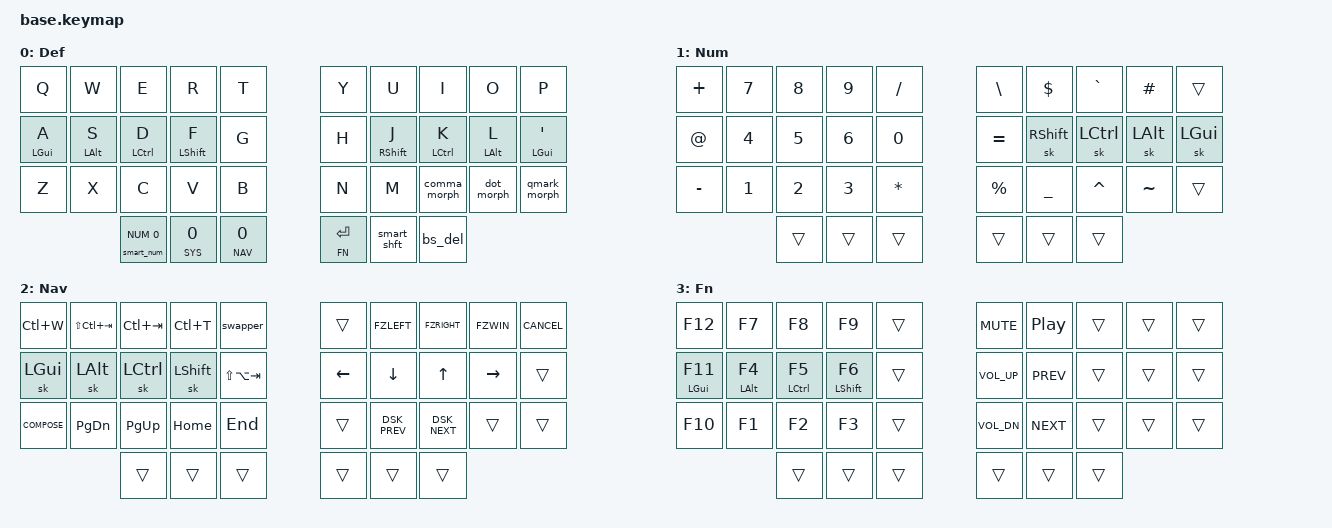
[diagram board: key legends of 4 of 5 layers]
#include <behaviors.dtsi>
#include <dt-bindings/zmk/keys.h>

/* layer and key shortcuts */
#include <dt-bindings/zmk/bt.h>
#include "../zmk-nodefree-config/helper.h"

#define _BT_SEL_KEYS_ &bt BT_SEL 0 &bt BT_SEL 1 &bt BT_SEL 2 &bt BT_SEL 3 &bt BT_CLR

#define DEF 0  // layer shortcuts, must match order in which they are defined below
#define NUM 1
#define NAV 2
#define FN  3
#define SYS 4
// #define MOUSE 5

#define KEYS_L LT0 LT1 LT2 LT3 LT4 LM0 LM1 LM2 LM3 LM4 LB0 LB1 LB2 LB3 LB4  // left hand
#define KEYS_R RT0 RT1 RT2 RT3 RT4 RM0 RM1 RM2 RM3 RM4 RB0 RB1 RB2 RB3 RB4  // right hand
#define KEYS_T LH2 LH1 LH0 RH0 RH1 RH2   // thumbs


#include "includes/macros.dtsi"
#include "includes/mods.dtsi"
#include "includes/dance.dtsi"
#include "includes/morphs.dtsi" // requires layer aliases
// #include "includes/mouse.dtsi"

#define XXX &none
#define ___ &trans

/* Global settings */


&sk {  // sticky-key config
    release-after-ms = <900>;  // release after 0.6s
    quick-release;             // no double capitalization when rolling keys
};

&mt {
  tapping-term-ms = <200>;
};

&lt {  // layer-tap config
  flavor = "balanced";
  tapping-term-ms = <200>;
  require-prior-idle-ms = <175>;
};

&sl {  // sticky-layer config
    ignore-modifiers;          // allow chording sticky mods & layers
};
#define FZLEFT     LC(LA(LG(LEFT)))
#define FZRIGHT    LC(LA(LG(RIGHT)))
#define FZWIN      LG(PG_UP)            // desktop manager
#define MEH        LC(LS(LALT))
#define COMPOSE    K_CMENU
#define CANCEL     K_CANCEL             // cancel caps-word, num-word and smart-mouse

// misc aliases
#define DSK_PREV   LG(LC(LEFT))  // previous desktop
#define DSK_NEXT   LG(LC(RIGHT))  // next     desktop

&caps_word {  // mods deactivate caps-word, requires PR #1451
    /delete-property/ ignore-modifiers;
};

// tap: num-word | double-tap: sticky num-layer | hold: num-layer
#define SMART_NUM &smart_num NUM 0

&num_word {  // num-word, requires PR #1451
    layers = <NUM>;
    continue-list = <BSPC DEL DOT COMMA PLUS MINUS STAR FSLH EQUAL>;
};

/*                KEY POSITIONS

  ╭─────────────────────╮ ╭─────────────────────╮
  │ LT4 LT3 LT2 LT1 LT0 │ │ RT0 RT1 RT2 RT3 RT4 │
  │ LM4 LM3 LM2 LM1 LM0 │ │ RM0 RM1 RM2 RM3 RM4 │
  │ LB4 LB3 LB2 LB1 LB0 │ │ RB0 RB1 RB2 RB3 RB4 │
  ╰───────╮ LH2 LH1 LH0 │ │ RH0 RH1 RH2 ╭───────╯
          ╰─────────────╯ ╰─────────────╯ */

// use require-prior-idle-ms for combos
#undef COMBO_HOOK
#define COMBO_HOOK require-prior-idle-ms = <150>;
#define COMBO_TERM_FAST 18
#define COMBO_TERM_SLOW 30
/* Horizontal combos - left hand */
ZMK_COMBO(esc,   &kp ESC,       LT0 LT1,     DEF NAV NUM FN SYS, COMBO_TERM_SLOW)
/* Horizontal combos - right hand */
ZMK_COMBO(amps,  &kp AMPS,      RT0 RT1,     DEF, COMBO_TERM_SLOW)
ZMK_COMBO(lbrc,  &kp LBRC,      RT1 RT2,     DEF, COMBO_TERM_SLOW)
ZMK_COMBO(rbrc,  &kp RBRC,      RT2 RT3,     DEF, COMBO_TERM_SLOW)
ZMK_COMBO(lpar,  &kp LPAR,      RM1 RM2,     DEF, COMBO_TERM_SLOW)
ZMK_COMBO(rpar,  &kp RPAR,      RM2 RM3,     DEF, COMBO_TERM_SLOW)
ZMK_COMBO(pipe,  &kp PIPE,      RB0 RB1,     DEF, COMBO_TERM_SLOW)
ZMK_COMBO(lbrk,  &kp LBKT,      RB1 RB2,     DEF, COMBO_TERM_SLOW)
ZMK_COMBO(rbrk,  &kp RBKT,      RB2 RB3,     DEF, COMBO_TERM_SLOW)

/* keymap */
/ {
   
  keymap {
    compatible = "zmk,keymap";

    def_layer {
      label ="Def";
      bindings = <
            &kp Q         &kp W         &kp E         &kp R         &kp T             &kp Y         &kp U         &kp I         &kp O         &kp P
            &hml LGUI A   &hml LALT S   &hml LCTRL D  &hml LSHFT F  &kp G             &kp H         &hmr RSHFT J  &hmr LCTRL K  &hmr LALT L   &hmr LGUI SQT
            &kp Z         &kp X         &kp C         &kp V         &kp B             &kp N         &kp M         &comma_morph  &dot_morph    &qmark_morph
                                        SMART_NUM     &lt_esc SYS 0 &lt_spc NAV 0     &lt FN RET    &smart_shft   &bs_del
      >;
    };

    num_layer {
    label = "Num";
      bindings = <
        &kp PLUS          &kp N7        &kp N8        &kp N9        &kp FSLH          &kp BSLH      &kp DLLR      &kp GRAVE     &kp HASH      ___
        &kp AT            &kp N4        &kp N5        &kp N6        &kp N0            &kp EQUAL     &sk RSHFT     &sk LCTRL     &sk LALT      &sk LGUI
        &kp MINUS         &kp N1        &kp N2        &kp N3        &kp STAR          &kp PRCNT     &kp UNDER     &kp CARET     &kp TILDE     ___
                                    ___           ___           ___                   ___           ___           ___
      >;
    };

    nav_layer {
      label = "Nav";
      bindings = <
            &kp LC(W) &kp LS(LC(TAB))   &kp LC(TAB)   &kp LC(T)     &swapper          ___           &kp FZLEFT    &kp FZRIGHT   &kp FZWIN   &kp CANCEL 
            &sk LGUI      &sk LALT      &sk LCTRL     &sk LSHFT     &kp LS(LA(TAB))   &kp LEFT      &kp DOWN      &kp UP        &kp RIGHT   ___
            &kp COMPOSE   &kp PG_DN     &kp PG_UP     &kp HOME      &kp END           ___           &kp DSK_PREV  &kp DSK_NEXT  ___         ___
                                        ___           ___           ___               ___           ___           ___
      >;
    };

    fn_layer {
      label = "Fn";
      bindings = <
            &kp F12       &kp F7        &kp F8        &kp F9        ___               &kp C_MUTE    &kp C_PP      ___           ___         ___  
            &hml LGUI F11 &hml LALT F4  &hml LCTRL F5 &hml LSHFT F6 ___               &kp C_VOL_UP  &kp C_PREV    ___           ___         ___  
            &kp F10       &kp F1        &kp F2        &kp F3        ___               &kp C_VOL_DN  &kp C_NEXT    ___           ___         ___  
                                        ___           ___           ___               ___           ___           ___
    >;
    };


    sys_layer {
      label = "Sys";
      bindings = <
                                      _BT_SEL_KEYS_                                   ___           ___           ___           ___           ___
            ___           ___           &kp STAR      ___           &bootloader       &bootloader   ___           ___           ___           ___
            ___           ___           ___           ___           &sys_reset        &sys_reset    ___           ___           ___           ___
                                        ___           ___           ___               ___           ___           ___
      >;
    };

    // mouse_layer {
    //   label = "Mouse";
    //   bindings = <
    //         ___           ___           ___           ___           ___               ___           U_WH_D        U_MS_U         U_WH_U       ___
    //         ___           ___           &kp STAR      &kp STAR      ___               ___           U_MS_L        U_MS_D         U_MS_R       ___
    //         ___           ___           ___           ___           ___               ___           ___           ___            ___          ___
    //                                     U_BTN1         U_BTN3       U_BTN2            U_BTN1        U_BTN3        U_BTN2
    // >;
   // };
 };
};
  /* vim: set filetype=c : */
